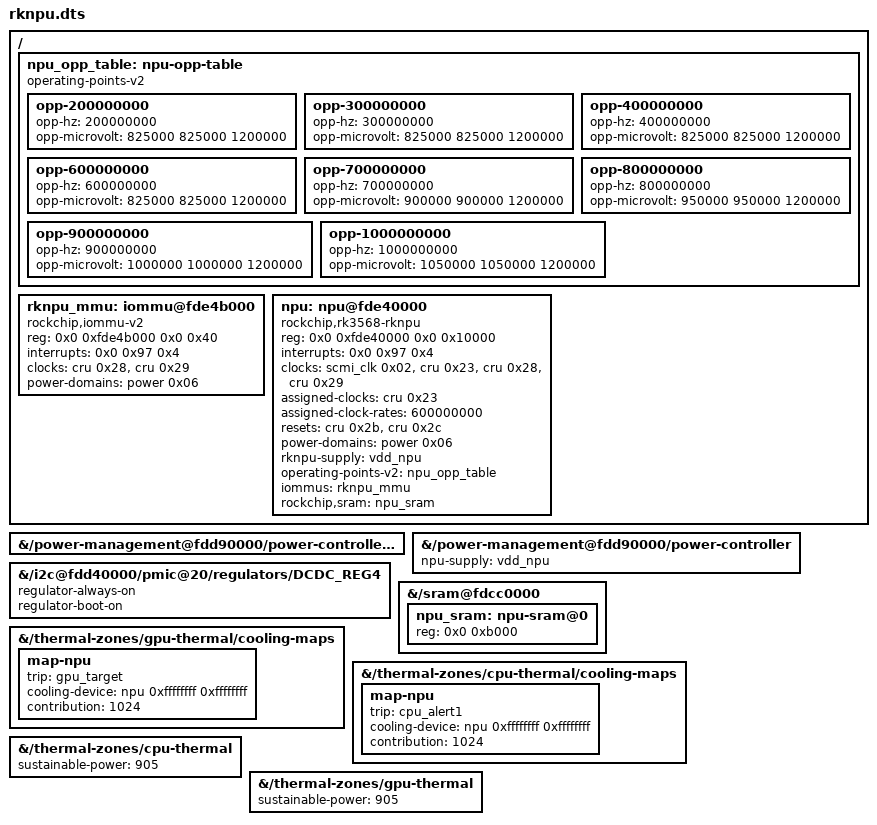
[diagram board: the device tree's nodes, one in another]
/dts-v1/;
/plugin/;

/ {
	/* Enable PD6 (NPU power domain) */
	fragment@0 {
		target-path = "/power-management@fdd90000/power-controller/power-domain@6";
		__overlay__ {
			status = "okay";
		};
	};

	/* Wire npu-supply to power controller */
	fragment@1 {
		target-path = "/power-management@fdd90000/power-controller";
		__overlay__ {
			npu-supply = <&vdd_npu>;
		};
	};

	/* Force vdd_npu regulator always-on (defines vdd_npu label for overlay) */
	fragment@2 {
		target-path = "/i2c@fdd40000/pmic@20/regulators/DCDC_REG4";
		vdd_npu: __overlay__ {
			regulator-always-on;
			regulator-boot-on;
		};
	};

	/* Create (or merge into) NPU, IOMMU, and OPP table nodes at root.
	 * On kernels where the stock DTB omits these nodes (e.g. mainline 6.18+),
	 * they are created. On BSP-derived kernels where they already exist,
	 * properties are merged harmlessly. */
	fragment@3 {
		target-path = "/";
		__overlay__ {
			npu_opp_table: npu-opp-table {
				compatible = "operating-points-v2";

				opp-200000000 {
					opp-hz = /bits/ 64 <200000000>;
					opp-microvolt = <825000 825000 1200000>;
				};
				opp-300000000 {
					opp-hz = /bits/ 64 <300000000>;
					opp-microvolt = <825000 825000 1200000>;
				};
				opp-400000000 {
					opp-hz = /bits/ 64 <400000000>;
					opp-microvolt = <825000 825000 1200000>;
				};
				opp-600000000 {
					opp-hz = /bits/ 64 <600000000>;
					opp-microvolt = <825000 825000 1200000>;
				};
				opp-700000000 {
					opp-hz = /bits/ 64 <700000000>;
					opp-microvolt = <900000 900000 1200000>;
				};
				opp-800000000 {
					opp-hz = /bits/ 64 <800000000>;
					opp-microvolt = <950000 950000 1200000>;
				};
				opp-900000000 {
					opp-hz = /bits/ 64 <900000000>;
					opp-microvolt = <1000000 1000000 1200000>;
				};
				opp-1000000000 {
					opp-hz = /bits/ 64 <1000000000>;
					opp-microvolt = <1050000 1050000 1200000>;
				};
			};

			rknpu_mmu: iommu@fde4b000 {
				compatible = "rockchip,iommu-v2";
				reg = <0x0 0xfde4b000 0x0 0x40>;
				interrupts = <0x0 0x97 0x4>;
				interrupt-names = "rknpu_mmu";
				clocks = <&cru 0x28>, <&cru 0x29>;
				clock-names = "aclk", "iface";
				power-domains = <&power 0x06>;
				#iommu-cells = <0>;
				status = "okay";
			};

			npu: npu@fde40000 {
				compatible = "rockchip,rk3568-rknpu", "rockchip,rknpu";
				reg = <0x0 0xfde40000 0x0 0x10000>;
				interrupts = <0x0 0x97 0x4>;
				clocks = <&scmi_clk 0x02>,
					 <&cru 0x23>,
					 <&cru 0x28>,
					 <&cru 0x29>;
				clock-names = "scmi_clk", "clk", "aclk", "hclk";
				assigned-clocks = <&cru 0x23>;
				assigned-clock-rates = <600000000>;
				resets = <&cru 0x2b>, <&cru 0x2c>;
				reset-names = "srst_a", "srst_h";
				power-domains = <&power 0x06>;
				rknpu-supply = <&vdd_npu>;
				operating-points-v2 = <&npu_opp_table>;
				iommus = <&rknpu_mmu>;
				#cooling-cells = <2>;
				rockchip,sram = <&npu_sram>; /* SRAM_PHANDLE */
				status = "okay";
			};
		};
	};

	/* SRAM_SPLIT_BEGIN — replaced by install.sh based on RKNPU_SRAM_PERCENT */
	fragment@6 {
		target-path = "/sram@fdcc0000";
		__overlay__ {
			#address-cells = <1>;
			#size-cells = <1>;

			npu_sram: npu-sram@0 {
				reg = <0x0 0xb000>;
			};
		};
	};
	/* SRAM_SPLIT_END */

	/* Bind NPU cooling to both thermal zones at 75°C trips.
	 * RK3568 has 2 TSADC channels: ch0=CPU, ch1=GPU. No NPU sensor.
	 * Binding to both ensures throttling regardless of which sensor heats first.
	 * contribution=1024 matches Rockchip 6.6 reference (equal weight). */
	fragment@8 {
		target-path = "/thermal-zones/gpu-thermal/cooling-maps";
		__overlay__ {
			map-npu {
				trip = <&gpu_target>;
				cooling-device = <&npu 0xffffffff 0xffffffff>;
				contribution = <1024>;
			};
		};
	};

	fragment@9 {
		target-path = "/thermal-zones/cpu-thermal/cooling-maps";
		__overlay__ {
			map-npu {
				trip = <&cpu_alert1>;
				cooling-device = <&npu 0xffffffff 0xffffffff>;
				contribution = <1024>;
			};
		};
	};

	/* Set sustainable-power on cpu-thermal for fair_share governor.
	 * 905 mW matches Rockchip 6.6 reference for RK3568. */
	fragment@10 {
		target-path = "/thermal-zones/cpu-thermal";
		__overlay__ {
			sustainable-power = <905>;
		};
	};

	fragment@11 {
		target-path = "/thermal-zones/gpu-thermal";
		__overlay__ {
			sustainable-power = <905>;
		};
	};
};
